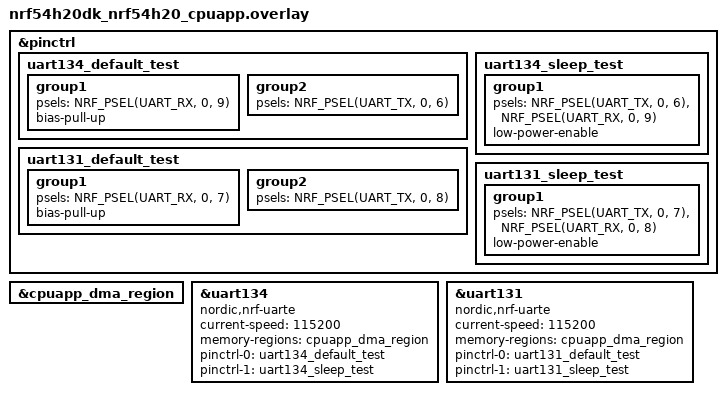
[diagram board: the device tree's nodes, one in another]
/*
 * Copyright (c) 2025 Nordic Semiconductor ASA
 *
 * SPDX-License-Identifier: LicenseRef-Nordic-5-Clause
 */

/*
 * Required loopbacks:
 * P0.08 <-> P0.09
 * P0.06 <-> P0.07
 */

&pinctrl {
	uart134_default_test: uart134_default_test {
		group1 {
			psels = <NRF_PSEL(UART_RX, 0, 9)>;
			bias-pull-up;
		};

		group2 {
			psels = <NRF_PSEL(UART_TX, 0, 6)>;
		};
	};

	uart134_sleep_test: uart134_sleep_test {
		group1 {
			psels = <NRF_PSEL(UART_TX, 0, 6)>,
				<NRF_PSEL(UART_RX, 0, 9)>;
			low-power-enable;
		};
	};

	uart131_default_test: uart131_default_test {
		group1 {
			psels = <NRF_PSEL(UART_RX, 0, 7)>;
			bias-pull-up;
		};

		group2 {
			psels = <NRF_PSEL(UART_TX, 0, 8)>;
		};
	};

	uart131_sleep_test: uart131_sleep_test {
		group1 {
			psels = <NRF_PSEL(UART_TX, 0, 7)>,
				<NRF_PSEL(UART_RX, 0, 8)>;
			low-power-enable;
		};
	};
};

&cpuapp_dma_region {
	status = "okay";
};

dut_uart_a: &uart134 {
	compatible = "nordic,nrf-uarte";
	current-speed = <115200>;
	status = "okay";
	memory-regions = <&cpuapp_dma_region>;
	pinctrl-0 = <&uart134_default_test>;
	pinctrl-1 = <&uart134_sleep_test>;
	pinctrl-names = "default", "sleep";
	/delete-property/ hw-flow-control;
};

dut_uart_b: &uart131 {
	compatible = "nordic,nrf-uarte";
	current-speed = <115200>;
	status = "okay";
	memory-regions = <&cpuapp_dma_region>;
	pinctrl-0 = <&uart131_default_test>;
	pinctrl-1 = <&uart131_sleep_test>;
	pinctrl-names = "default", "sleep";
	/delete-property/ hw-flow-control;
};
